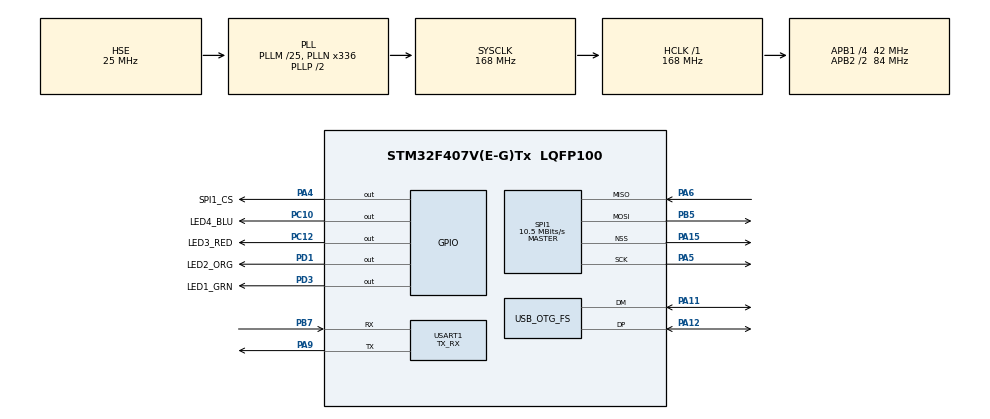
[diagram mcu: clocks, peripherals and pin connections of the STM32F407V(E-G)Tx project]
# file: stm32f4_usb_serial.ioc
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ADC1.Channel-1\#ChannelRegularConversion=ADC_CHANNEL_TEMPSENSOR
ADC1.NbrOfConversionFlag=1
ADC1.Rank-1\#ChannelRegularConversion=1
ADC1.SamplingTime-1\#ChannelRegularConversion=ADC_SAMPLETIME_3CYCLES
ADC1.master=1
Mcu.Family=STM32F4
Mcu.Name=STM32F407V(E-G)Tx
Mcu.Package=LQFP100
NVIC.OTG_FS_IRQn=true\:7\:0\:true\:false\:true\:false\:true\:true\:true
NVIC.PriorityGroup=NVIC_PRIORITYGROUP_4
NVIC.TIM8_TRG_COM_TIM14_IRQn=true\:1\:0\:true\:false\:true\:false\:false\:true\:true
NVIC.TimeBase=TIM8_TRG_COM_TIM14_IRQn
NVIC.TimeBaseIP=TIM14
NVIC.USART1_IRQn=true\:8\:0\:true\:false\:true\:false\:true\:true\:true
PA11.Mode=Device_Only
PA11.Signal=USB_OTG_FS_DM
PA12.Mode=Device_Only
PA12.Signal=USB_OTG_FS_DP
PA13.Mode=Trace_Asynchronous_SW
PA13.Signal=SYS_JTMS-SWDIO
PA14.Mode=Trace_Asynchronous_SW
PA14.Signal=SYS_JTCK-SWCLK
PA15.Mode=NSS_Signal_Hard_Output
PA15.Signal=SPI1_NSS
PA4.GPIO_Label=SPI1_CS
PA4.Signal=GPIO_Output
PA5.Mode=Full_Duplex_Master
PA5.Signal=SPI1_SCK
PA6.Mode=Full_Duplex_Master
PA6.Signal=SPI1_MISO
PA9.Mode=Asynchronous
PA9.Signal=USART1_TX
PB3.Mode=Trace_Asynchronous_SW
PB3.Signal=SYS_JTDO-SWO
PB5.Mode=Full_Duplex_Master
PB5.Signal=SPI1_MOSI
PB7.Mode=Asynchronous
PB7.Signal=USART1_RX
PC10.GPIO_Label=LED4_BLU
PC10.PinState=GPIO_PIN_SET
PC10.Signal=GPIO_Output
PC12.GPIO_Label=LED3_RED
PC12.PinState=GPIO_PIN_SET
PC12.Signal=GPIO_Output
PC14-OSC32_IN.Mode=LSE-External-Oscillator
PC14-OSC32_IN.Signal=RCC_OSC32_IN
PC15-OSC32_OUT.Mode=LSE-External-Oscillator
PC15-OSC32_OUT.Signal=RCC_OSC32_OUT
PD1.GPIO_Label=LED2_ORG
PD1.PinState=GPIO_PIN_SET
PD1.Signal=GPIO_Output
PD3.GPIO_Label=LED1_GRN
PD3.PinState=GPIO_PIN_SET
PD3.Signal=GPIO_Output
PH0-OSC_IN.Mode=HSE-External-Oscillator
PH0-OSC_IN.Signal=RCC_OSC_IN
PH1-OSC_OUT.Mode=HSE-External-Oscillator
PH1-OSC_OUT.Signal=RCC_OSC_OUT
ProjectManager.HeapSize=0x200
ProjectManager.StackSize=0x400
ProjectManager.TargetToolchain=STM32CubeIDE
RCC.48MHZClocksFreq_Value=48000000
RCC.AHBFreq_Value=168000000
RCC.APB1CLKDivider=RCC_HCLK_DIV4
RCC.APB1Freq_Value=42000000
RCC.APB1TimFreq_Value=84000000
RCC.APB2CLKDivider=RCC_HCLK_DIV2
RCC.APB2Freq_Value=84000000
RCC.APB2TimFreq_Value=168000000
RCC.CortexFreq_Value=168000000
RCC.HCLKFreq_Value=168000000
RCC.HSE_VALUE=25000000
RCC.HSI_VALUE=16000000
RCC.PLLM=25
RCC.PLLN=336
RCC.PLLQ=7
RCC.RCC_RTC_Clock_Source=RCC_RTCCLKSOURCE_LSE
RCC.RCC_RTC_Clock_SourceVirtual=RCC_RTCCLKSOURCE_LSE
RCC.SYSCLKFreq_VALUE=168000000
RCC.SYSCLKSource=RCC_SYSCLKSOURCE_PLLCLK
RCC.VCOOutputFreq_Value=336000000
SPI1.BaudRatePrescaler=SPI_BAUDRATEPRESCALER_8
SPI1.CalculateBaudRate=10.5 MBits/s
SPI1.Direction=SPI_DIRECTION_2LINES
SPI1.Mode=SPI_MODE_MASTER
SPI1.VirtualNSS=VM_NSSHARD
SPI1.VirtualType=VM_MASTER
STMicroelectronics.X-CUBE-AZRTOS-F4.1.1.0.AZRTOS_APP_MEM_ALLOCATION_METHOD=1
STMicroelectronics.X-CUBE-AZRTOS-F4.1.1.0.NX_APP_MEM_POOL_SIZE=30*1024
STMicroelectronics.X-CUBE-AZRTOS-F4.1.1.0.NX_ENABLE_INTERFACE_CAPABILITY=false
STMicroelectronics.X-CUBE-AZRTOS-F4.1.1.0.NX_SECURE_ALLOW_SELF_SIGNED_CERTIFICATES=true
STMicroelectronics.X-CUBE-AZRTOS-F4.1.1.0.NX_SECURE_ENABLE=true
STMicroelectronics.X-CUBE-AZRTOS-F4.1.1.0.NX_SECURE_ENABLE_CLIENT_CERTIFICATE_VERIFY=true
STMicroelectronics.X-CUBE-AZRTOS-F4.1.1.0.TX_APP_MEM_POOL_SIZE=5*1024
STMicroelectronics.X-CUBE-AZRTOS-F4.1.1.0.TX_ENABLE_STACK_CHECKING=1
STMicroelectronics.X-CUBE-AZRTOS-F4.1.1.0.ThreadXCcRTOSJjThreadXJjCore=true
STMicroelectronics.X-CUBE-AZRTOS-F4.1.1.0.USBD_CDCACM_EPINCMD_ADDR=2
STMicroelectronics.X-CUBE-AZRTOS-F4.1.1.0.USBD_CDCACM_EPIN_ADDR=3
STMicroelectronics.X-CUBE-AZRTOS-F4.1.1.0.USBD_CDCACM_EPOUT_ADDR=1
STMicroelectronics.X-CUBE-AZRTOS-F4.1.1.0.USBD_MANUFACTURER_STRING=easy-smart solution GmbH
STMicroelectronics.X-CUBE-AZRTOS-F4.1.1.0.USBD_PID=22336
STMicroelectronics.X-CUBE-AZRTOS-F4.1.1.0.USBD_PRODUCT_STRING=stm32f4_usb_serial
STMicroelectronics.X-CUBE-AZRTOS-F4.1.1.0.USBXCcUSBJjUSBXJjCoreSystem=true
STMicroelectronics.X-CUBE-AZRTOS-F4.1.1.0.USBXCcUSBJjUSBXJjUXOoDeviceOoClassOoCDCOoACM=true
STMicroelectronics.X-CUBE-AZRTOS-F4.1.1.0.USBXCcUSBJjUSBXJjUXOoDeviceOoControllers=true
STMicroelectronics.X-CUBE-AZRTOS-F4.1.1.0.USBXCcUSBJjUSBXJjUXOoDeviceOoCoreStack=true
STMicroelectronics.X-CUBE-AZRTOS-F4.1.1.0.UX_DEVICE_APP_MEM_POOL_SIZE=14*1024
STMicroelectronics.X-CUBE-AZRTOS-F4.1.1.0_IsAnAzureRtosMw=true
USART1.Mode=MODE_TX_RX
USART1.VirtualMode=VM_ASYNC
USB_OTG_FS.Sof_enable=DISABLE
USB_OTG_FS.VirtualMode=Device_Only
VP_ADC1_TempSens_Input.Mode=IN-TempSens
VP_ADC1_Vbat_Input.Mode=IN-Vbat
VP_ADC1_Vref_Input.Mode=IN-Vrefint
VP_CRC_VS_CRC.Mode=CRC_Activate
VP_RNG_VS_RNG.Mode=RNG_Activate
VP_RTC_VS_RTC_Activate.Mode=RTC_Enabled
VP_STMicroelectronics.X-CUBE-AZRTOS-F4_VS_RTOSJjThreadX_6.1.10_1.1.0.Mode=RTOSJjThreadX
VP_STMicroelectronics.X-CUBE-AZRTOS-F4_VS_USBJjUSBX_6.1.10_1.1.0.Mode=USBJjUSBX
VP_SYS_VS_tim14.Mode=TIM14
board=custom

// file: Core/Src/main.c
/* USER CODE BEGIN Header */
/**
  ******************************************************************************
  * @file           : main.c
  * @brief          : Main program body
  ******************************************************************************
  * @attention
  *
  * Copyright (c) 2024 STMicroelectronics.
  * All rights reserved.
  *
  * This software is licensed under terms that can be found in the LICENSE file
  * in the root directory of this software component.
  * If no LICENSE file comes with this software, it is provided AS-IS.
  *
  ******************************************************************************
  */
/* USER CODE END Header */
#include "app_threadx.h"
#include "main.h"
#include "adc.h"
#include "crc.h"
#include "rng.h"
#include "rtc.h"
#include "spi.h"
#include "usart.h"
#include "gpio.h"

/* USER CODE BEGIN Includes */
#include "defines.h"
#include "globals.h"
#include "main.hpp"
/* USER CODE END Includes */

/* USER CODE BEGIN PV */
Debugger* DBG=NULL;
/* USER CODE END PV */

void SystemClock_Config(void);

int main(void)
{

  /* MCU Configuration--------------------------------------------------------*/

  /* Reset of all peripherals, Initializes the Flash interface and the Systick. */
  HAL_Init();

  /* Configure the system clock */
  SystemClock_Config();

  /* Initialize all configured peripherals */
  MX_GPIO_Init();
  MX_RTC_Init();
  MX_SPI1_Init();
  MX_ADC1_Init();
  MX_CRC_Init();
  MX_RNG_Init();
  MX_USART1_UART_Init();
  /* USER CODE BEGIN 2 */

  // Jump to our C++ setup function
  setup();

  /* USER CODE END 2 */

  MX_ThreadX_Init();

  /* We should never get here as control is now taken by the scheduler */

  /* Infinite loop */
  while (1)
  {

  }
}

void SystemClock_Config(void)
{
  RCC_OscInitTypeDef RCC_OscInitStruct = {0};
  RCC_ClkInitTypeDef RCC_ClkInitStruct = {0};

  /** Configure the main internal regulator output voltage
  */
  __HAL_RCC_PWR_CLK_ENABLE();
  __HAL_PWR_VOLTAGESCALING_CONFIG(PWR_REGULATOR_VOLTAGE_SCALE1);

  /** Initializes the RCC Oscillators according to the specified parameters
  * in the RCC_OscInitTypeDef structure.
  */
  RCC_OscInitStruct.OscillatorType = RCC_OSCILLATORTYPE_HSE|RCC_OSCILLATORTYPE_LSE;
  RCC_OscInitStruct.HSEState = RCC_HSE_ON;
  RCC_OscInitStruct.LSEState = RCC_LSE_ON;
  RCC_OscInitStruct.PLL.PLLState = RCC_PLL_ON;
  RCC_OscInitStruct.PLL.PLLSource = RCC_PLLSOURCE_HSE;
  RCC_OscInitStruct.PLL.PLLM = 25;
  RCC_OscInitStruct.PLL.PLLN = 336;
  RCC_OscInitStruct.PLL.PLLP = RCC_PLLP_DIV2;
  RCC_OscInitStruct.PLL.PLLQ = 7;
  if (HAL_RCC_OscConfig(&RCC_OscInitStruct) != HAL_OK)
  {
    Error_Handler();
  }

  /** Initializes the CPU, AHB and APB buses clocks
  */
  RCC_ClkInitStruct.ClockType = RCC_CLOCKTYPE_HCLK|RCC_CLOCKTYPE_SYSCLK
                              |RCC_CLOCKTYPE_PCLK1|RCC_CLOCKTYPE_PCLK2;
  RCC_ClkInitStruct.SYSCLKSource = RCC_SYSCLKSOURCE_PLLCLK;
  RCC_ClkInitStruct.AHBCLKDivider = RCC_SYSCLK_DIV1;
  RCC_ClkInitStruct.APB1CLKDivider = RCC_HCLK_DIV4;
  RCC_ClkInitStruct.APB2CLKDivider = RCC_HCLK_DIV2;

  if (HAL_RCC_ClockConfig(&RCC_ClkInitStruct, FLASH_LATENCY_5) != HAL_OK)
  {
    Error_Handler();
  }
}

void HAL_TIM_PeriodElapsedCallback(TIM_HandleTypeDef *htim)
{
  if (htim->Instance == TIM14) {
    HAL_IncTick();
  }
}

void Error_Handler(void)
{
  /* USER CODE BEGIN Error_Handler_Debug */
  /* User can add his own implementation to report the HAL error return state */
  __disable_irq();

  // Jump to our C++ setup function
  errorHandler();

  while (1)
  {
  }
  /* USER CODE END Error_Handler_Debug */
}
